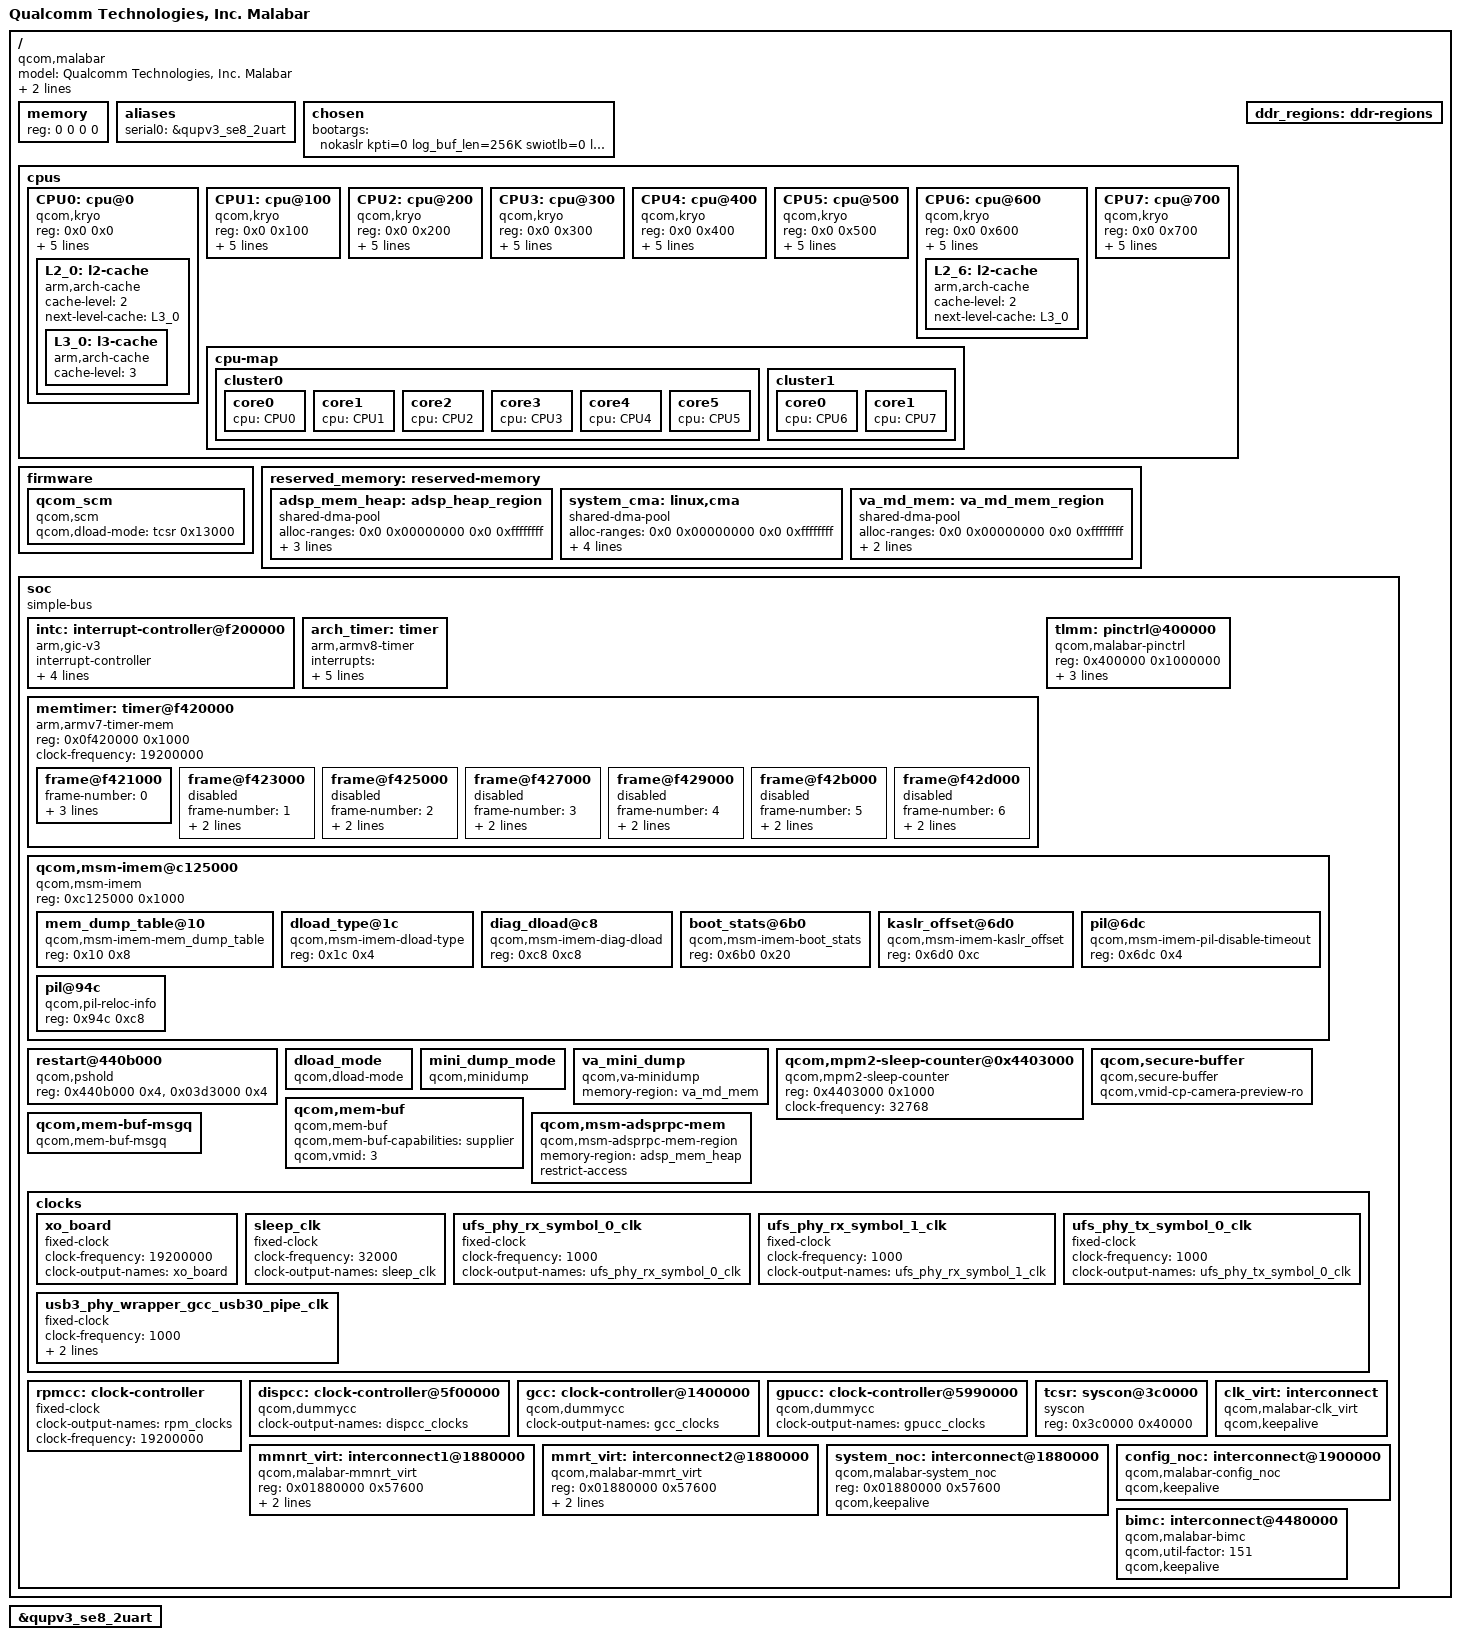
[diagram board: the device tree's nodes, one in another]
// SPDX-License-Identifier: BSD-3-Clause
/*
 * Copyright (c) Qualcomm Technologies, Inc. and/or its subsidiaries.
 */
#include <dt-bindings/interrupt-controller/arm-gic.h>
#include <dt-bindings/clock/qcom,rpmcc.h>
#include <dt-bindings/clock/qcom,malabar-dispcc.h>
#include <dt-bindings/clock/qcom,malabar-gcc.h>
#include <dt-bindings/clock/qcom,malabar-gpucc.h>
#include <dt-bindings/interconnect/qcom,icc.h>
#include <dt-bindings/interconnect/qcom,malabar.h>

/ {
	model = "Qualcomm Technologies, Inc. Malabar";
	compatible = "qcom,malabar";
	qcom,msm-id = <733 0x10000>;
	interrupt-parent = <&intc>;

	#address-cells = <2>;
	#size-cells = <2>;
	memory { device_type = "memory"; reg = <0 0 0 0>; };

	aliases {
		serial0 = &qupv3_se8_2uart;
	 };

	chosen: chosen {
		bootargs = "nokaslr kpti=0 log_buf_len=256K swiotlb=0 loop.max_part=7 swiotlb=0 kasan=off cgroup_disable=pressure cgroup.memory=nokmem,nosocket disable_dma32=on page_poison=on restrict_cma_redirect=false";
	};

	cpus {
		#address-cells = <2>;
		#size-cells = <0>;

		CPU0: cpu@0 {
			device_type = "cpu";
			compatible = "qcom,kryo";
			reg = <0x0 0x0>;
			enable-method = "spin-table"; /* TODO: Update to psci */
			cpu-release-addr = <0x0 0xE3940000>;
			next-level-cache = <&L2_0>;
			capacity-dmips-mhz = <1024>;
			dynamic-power-coefficient = <100>;
			L2_0: l2-cache {
			      compatible = "arm,arch-cache";
			      cache-level = <2>;
			      next-level-cache = <&L3_0>;

				L3_0: l3-cache {
					compatible = "arm,arch-cache";
					cache-level = <3>;
				};
			};
		};

		CPU1: cpu@100 {
			device_type = "cpu";
			compatible = "qcom,kryo";
			reg = <0x0 0x100>;
			enable-method = "spin-table"; /* TODO: Update to psci */
			cpu-release-addr = <0x0 0xE3940000>;
			capacity-dmips-mhz = <1024>;
			dynamic-power-coefficient = <100>;
			next-level-cache = <&L2_0>;
		};

		CPU2: cpu@200 {
			device_type = "cpu";
			compatible = "qcom,kryo";
			reg = <0x0 0x200>;
			enable-method = "spin-table"; /* TODO: Update to psci */
			cpu-release-addr = <0x0 0xE3940000>;
			capacity-dmips-mhz = <1024>;
			dynamic-power-coefficient = <100>;
			next-level-cache = <&L2_0>;
		};

		CPU3: cpu@300 {
			device_type = "cpu";
			compatible = "qcom,kryo";
			reg = <0x0 0x300>;
			enable-method = "spin-table"; /* TODO: Update to psci */
			cpu-release-addr = <0x0 0xE3940000>;
			capacity-dmips-mhz = <1024>;
			dynamic-power-coefficient = <100>;
			next-level-cache = <&L2_0>;
		};

		CPU4: cpu@400 {
			device_type = "cpu";
			compatible = "qcom,kryo";
			reg = <0x0 0x400>;
			enable-method = "spin-table"; /* TODO: Update to psci */
			cpu-release-addr = <0x0 0xE3940000>;
			capacity-dmips-mhz = <1024>;
			dynamic-power-coefficient = <100>;
			next-level-cache = <&L2_0>;
		};

		CPU5: cpu@500 {
			device_type = "cpu";
			compatible = "qcom,kryo";
			reg = <0x0 0x500>;
			enable-method = "spin-table"; /* TODO: Update to psci */
			cpu-release-addr = <0x0 0xE3940000>;
			capacity-dmips-mhz = <1024>;
			dynamic-power-coefficient = <100>;
			next-level-cache = <&L2_0>;
		};

		CPU6: cpu@600 {
			device_type = "cpu";
			compatible = "qcom,kryo";
			reg = <0x0 0x600>;
			enable-method = "spin-table"; /* TODO: Update to psci */
			cpu-release-addr = <0x0 0xE3940000>;
			capacity-dmips-mhz = <1946>;
			dynamic-power-coefficient = <489>;
			next-level-cache = <&L2_6>;
			L2_6: l2-cache {
			      compatible = "arm,arch-cache";
			      cache-level = <2>;
			      next-level-cache = <&L3_0>;
			};
		};

		CPU7: cpu@700 {
			device_type = "cpu";
			compatible = "qcom,kryo";
			reg = <0x0 0x700>;
			enable-method = "spin-table"; /* TODO: Update to psci */
			cpu-release-addr = <0x0 0xE3940000>;
			capacity-dmips-mhz = <1946>;
			dynamic-power-coefficient = <489>;
			next-level-cache = <&L2_6>;
		};

		cpu-map {
			cluster0 {
				core0 {
					cpu = <&CPU0>;
				};

				core1 {
					cpu = <&CPU1>;
				};

				core2 {
					cpu = <&CPU2>;
				};

				core3 {
					cpu = <&CPU3>;
				};

				core4 {
					cpu = <&CPU4>;
				};

				core5 {
					cpu = <&CPU5>;
				};
			};

			cluster1 {
				core0 {
					cpu = <&CPU6>;
				};

				core1 {
					cpu = <&CPU7>;
				};
			};
		};
	};

	ddr_regions: ddr-regions { };

	firmware: firmware {
		qcom_scm: qcom_scm { };
	};

	reserved_memory: reserved-memory { };

	soc: soc { };
};

#include "malabar-reserved-memory.dtsi"
#include "msm-arm-smmu-malabar.dtsi"
#include "malabar-dma-heaps.dtsi"

&reserved_memory {
	#address-cells = <2>;
	#size-cells = <2>;
	ranges;

	adsp_mem_heap: adsp_heap_region {
		compatible = "shared-dma-pool";
		alloc-ranges = <0x0 0x00000000 0x0 0xffffffff>;
		reusable;
		alignment = <0x0 0x400000>;
		size = <0x0 0xC00000>;
	};

	/* global autoconfigured region for contiguous allocations */
	system_cma: linux,cma {
		compatible = "shared-dma-pool";
		alloc-ranges = <0x0 0x00000000 0x0 0xffffffff>;
		reusable;
		alignment = <0x0 0x400000>;
		size = <0x0 0x2000000>;
		linux,cma-default;
	};

	va_md_mem: va_md_mem_region {
		compatible = "shared-dma-pool";
		alloc-ranges = <0x0 0x00000000 0x0 0xffffffff>;
		reusable;
		size = <0 0x1000000>;
	};
};

&firmware {
	qcom_scm {
		compatible = "qcom,scm";
		qcom,dload-mode = <&tcsr 0x13000>;
	};
};

&soc {
	#address-cells = <1>;
	#size-cells = <1>;
	ranges = <0 0 0 0xffffffff>;
	compatible = "simple-bus";

	intc: interrupt-controller@f200000 {
		compatible = "arm,gic-v3";
		#interrupt-cells = <3>;
		interrupt-controller;
		#redistributor-regions = <1>;
		redistributor-stride = <0x0 0x20000>;
		reg = <0xf200000 0x10000>,     /* GICD */
		      <0xf240000 0x100000>;    /* GICR * 8 */
		interrupts = <GIC_PPI 8 IRQ_TYPE_LEVEL_HIGH>;
	};

	arch_timer: timer {
		compatible = "arm,armv8-timer";
		interrupts = <GIC_PPI 1 (GIC_CPU_MASK_SIMPLE(8) | IRQ_TYPE_LEVEL_LOW)>,
			     <GIC_PPI 2 (GIC_CPU_MASK_SIMPLE(8) | IRQ_TYPE_LEVEL_LOW)>,
			     <GIC_PPI 3 (GIC_CPU_MASK_SIMPLE(8) | IRQ_TYPE_LEVEL_LOW)>,
			     <GIC_PPI 0 (GIC_CPU_MASK_SIMPLE(8) | IRQ_TYPE_LEVEL_LOW)>;
		clock-frequency = <19200000>;
	};

	memtimer: timer@f420000 {
		#address-cells = <1>;
		#size-cells = <1>;
		ranges;
		compatible = "arm,armv7-timer-mem";
		reg = <0x0f420000 0x1000>;
		clock-frequency = <19200000>;

		frame@f421000 {
			frame-number = <0>;
			interrupts = <GIC_SPI 8 IRQ_TYPE_LEVEL_HIGH>,
				     <GIC_SPI 6 IRQ_TYPE_LEVEL_HIGH>;
			reg = <0x0f421000 0x1000>,
			      <0x0f422000 0x1000>;
		};

		frame@f423000 {
			frame-number = <1>;
			interrupts = <GIC_SPI 9 IRQ_TYPE_LEVEL_HIGH>;
			reg = <0xf243000 0x1000>;
			status = "disabled";
		};

		frame@f425000 {
			frame-number = <2>;
			interrupts = <GIC_SPI 10 IRQ_TYPE_LEVEL_HIGH>;
			reg = <0xf425000 0x1000>;
			status = "disabled";
		};

		frame@f427000 {
			frame-number = <3>;
			interrupts = <GIC_SPI 11 IRQ_TYPE_LEVEL_HIGH>;
			reg = <0xf427000 0x1000>;
			status = "disabled";
		};

		frame@f429000 {
			frame-number = <4>;
			interrupts = <GIC_SPI 12 IRQ_TYPE_LEVEL_HIGH>;
			reg = <0xf429000 0x1000>;
			status = "disabled";
		};

		frame@f42b000 {
			frame-number = <5>;
			interrupts = <GIC_SPI 13 IRQ_TYPE_LEVEL_HIGH>;
			reg = <0xf42b000 0x1000>;
			status = "disabled";
		};

		frame@f42d000 {
			frame-number = <6>;
			interrupts = <GIC_SPI 14 IRQ_TYPE_LEVEL_HIGH>;
			reg = <0xf42d000 0x1000>;
			status = "disabled";
		};
	};

	tlmm: pinctrl@400000 {
		compatible = "qcom,malabar-pinctrl";
		reg = <0x400000 0x1000000>;
		interrupts = <GIC_SPI 227 IRQ_TYPE_LEVEL_HIGH>;
		gpio-controller;
		#gpio-cells = <2>;
		interrupt-controller;
		#interrupt-cells = <2>;
	};

	qcom,msm-imem@c125000 {
		compatible = "qcom,msm-imem";
		reg = <0xc125000 0x1000>;
		ranges = <0x0 0xc125000 0x1000>;
		#address-cells = <1>;
		#size-cells = <1>;

		mem_dump_table@10 {
			compatible = "qcom,msm-imem-mem_dump_table";
			reg = <0x10 0x8>;
		};

		dload_type@1c {
			compatible = "qcom,msm-imem-dload-type";
			reg = <0x1c 0x4>;
		};

		diag_dload@c8 {
			compatible = "qcom,msm-imem-diag-dload";
			reg = <0xc8 0xc8>;
		};

		boot_stats@6b0 {
			compatible = "qcom,msm-imem-boot_stats";
			reg = <0x6b0 0x20>;
		};

		kaslr_offset@6d0 {
			compatible = "qcom,msm-imem-kaslr_offset";
			reg = <0x6d0 0xc>;
		};

		pil@6dc {
			compatible = "qcom,msm-imem-pil-disable-timeout";
			reg = <0x6dc 0x4>;
		};

		pil@94c {
			compatible = "qcom,pil-reloc-info";
			reg = <0x94c 0xc8>;
		};
	};

	restart@440b000 {
		compatible = "qcom,pshold";
		reg = <0x440b000 0x4>, <0x03d3000 0x4>;
		reg-names = "pshold-base", "tcsr-boot-misc-detect";
	};

	dload_mode {
		compatible = "qcom,dload-mode";
	};

	mini_dump_mode {
		compatible = "qcom,minidump";
	};

	va_mini_dump {
		compatible = "qcom,va-minidump";
		memory-region = <&va_md_mem>;
	};

	qcom,mpm2-sleep-counter@0x4403000 {
		compatible = "qcom,mpm2-sleep-counter";
		reg = <0x4403000 0x1000>;
		clock-frequency = <32768>;
	};

	qcom,secure-buffer {
		compatible = "qcom,secure-buffer";
		qcom,vmid-cp-camera-preview-ro;
	};

	qcom,mem-buf {
		compatible = "qcom,mem-buf";
		qcom,mem-buf-capabilities = "supplier";
		qcom,vmid = <3>;
	};

	qcom,mem-buf-msgq {
		compatible = "qcom,mem-buf-msgq";
	};

	qcom,msm-adsprpc-mem {
		compatible = "qcom,msm-adsprpc-mem-region";
		memory-region = <&adsp_mem_heap>;
		restrict-access;
	};

	clocks {
		xo_board: xo_board {
			compatible = "fixed-clock";
			clock-frequency = <19200000>;
			clock-output-names = "xo_board";
			#clock-cells = <0>;
		};

		sleep_clk: sleep_clk {
			compatible = "fixed-clock";
			clock-frequency = <32000>;
			clock-output-names = "sleep_clk";
			#clock-cells = <0>;
		};

		ufs_phy_rx_symbol_0_clk: ufs_phy_rx_symbol_0_clk {
			compatible = "fixed-clock";
			clock-frequency = <1000>;
			clock-output-names = "ufs_phy_rx_symbol_0_clk";
			#clock-cells = <0>;
		};

		ufs_phy_rx_symbol_1_clk: ufs_phy_rx_symbol_1_clk {
			compatible = "fixed-clock";
			clock-frequency = <1000>;
			clock-output-names = "ufs_phy_rx_symbol_1_clk";
			#clock-cells = <0>;
		};

		ufs_phy_tx_symbol_0_clk: ufs_phy_tx_symbol_0_clk {
			compatible = "fixed-clock";
			clock-frequency = <1000>;
			clock-output-names = "ufs_phy_tx_symbol_0_clk";
			#clock-cells = <0>;
		};

		usb3_phy_wrapper_gcc_usb30_pipe_clk: usb3_phy_wrapper_gcc_usb30_pipe_clk {
			compatible = "fixed-clock";
			clock-frequency = <1000>;
			clock-output-names = "usb3_phy_wrapper_gcc_usb30_pipe_clk";
			#clock-cells = <0>;
		};
	};

	rpmcc: clock-controller {
		compatible = "fixed-clock";
		clock-output-names = "rpm_clocks";
		clock-frequency = <19200000>;
		#clock-cells = <1>;
	};

	dispcc: clock-controller@5f00000 {
		compatible = "qcom,dummycc";
		clock-output-names = "dispcc_clocks";
		#clock-cells = <1>;
		#reset-cells = <1>;
		#power-domain-cells = <1>;
	};

	gcc: clock-controller@1400000 {
		compatible = "qcom,dummycc";
		clock-output-names = "gcc_clocks";
		#clock-cells = <1>;
		#reset-cells = <1>;
		#power-domain-cells = <1>;
	};

	gpucc: clock-controller@5990000 {
		compatible = "qcom,dummycc";
		clock-output-names = "gpucc_clocks";
		#clock-cells = <1>;
		#reset-cells = <1>;
		#power-domain-cells = <1>;
	};

	tcsr: syscon@3c0000 {
		compatible = "syscon";
		reg = <0x3c0000 0x40000>;
	};

	clk_virt: interconnect {
		compatible = "qcom,malabar-clk_virt";
		#interconnect-cells = <1>;
		qcom,keepalive;
	};

	mmnrt_virt: interconnect1@1880000 {
		reg = <0x01880000 0x57600>;
		compatible = "qcom,malabar-mmnrt_virt";
		#interconnect-cells = <1>;
		qcom,util-factor = <142>;
		qcom,keepalive;
	};

	mmrt_virt: interconnect2@1880000 {
		reg = <0x01880000 0x57600>;
		compatible = "qcom,malabar-mmrt_virt";
		#interconnect-cells = <1>;
		qcom,util-factor = <142>;
		qcom,keepalive;
	};

	system_noc: interconnect@1880000 {
		reg = <0x01880000 0x57600>;
		compatible = "qcom,malabar-system_noc";
		#interconnect-cells = <1>;
		qcom,keepalive;
	};

	config_noc: interconnect@1900000 {
		compatible = "qcom,malabar-config_noc";
		#interconnect-cells = <1>;
		qcom,keepalive;
	};

	bimc: interconnect@4480000 {
		compatible = "qcom,malabar-bimc";
		#interconnect-cells = <1>;
		qcom,util-factor = <151>;
		qcom,keepalive;
	};
};
#include "malabar-coresight.dtsi"
#include "malabar-debug.dtsi"
#include "malabar-stub-regulators.dtsi"
#include "malabar-pinctrl.dtsi"
#include "malabar-qupv3.dtsi"

&qupv3_se8_2uart {
	status = "ok";
};

#include "malabar-usb.dtsi"
